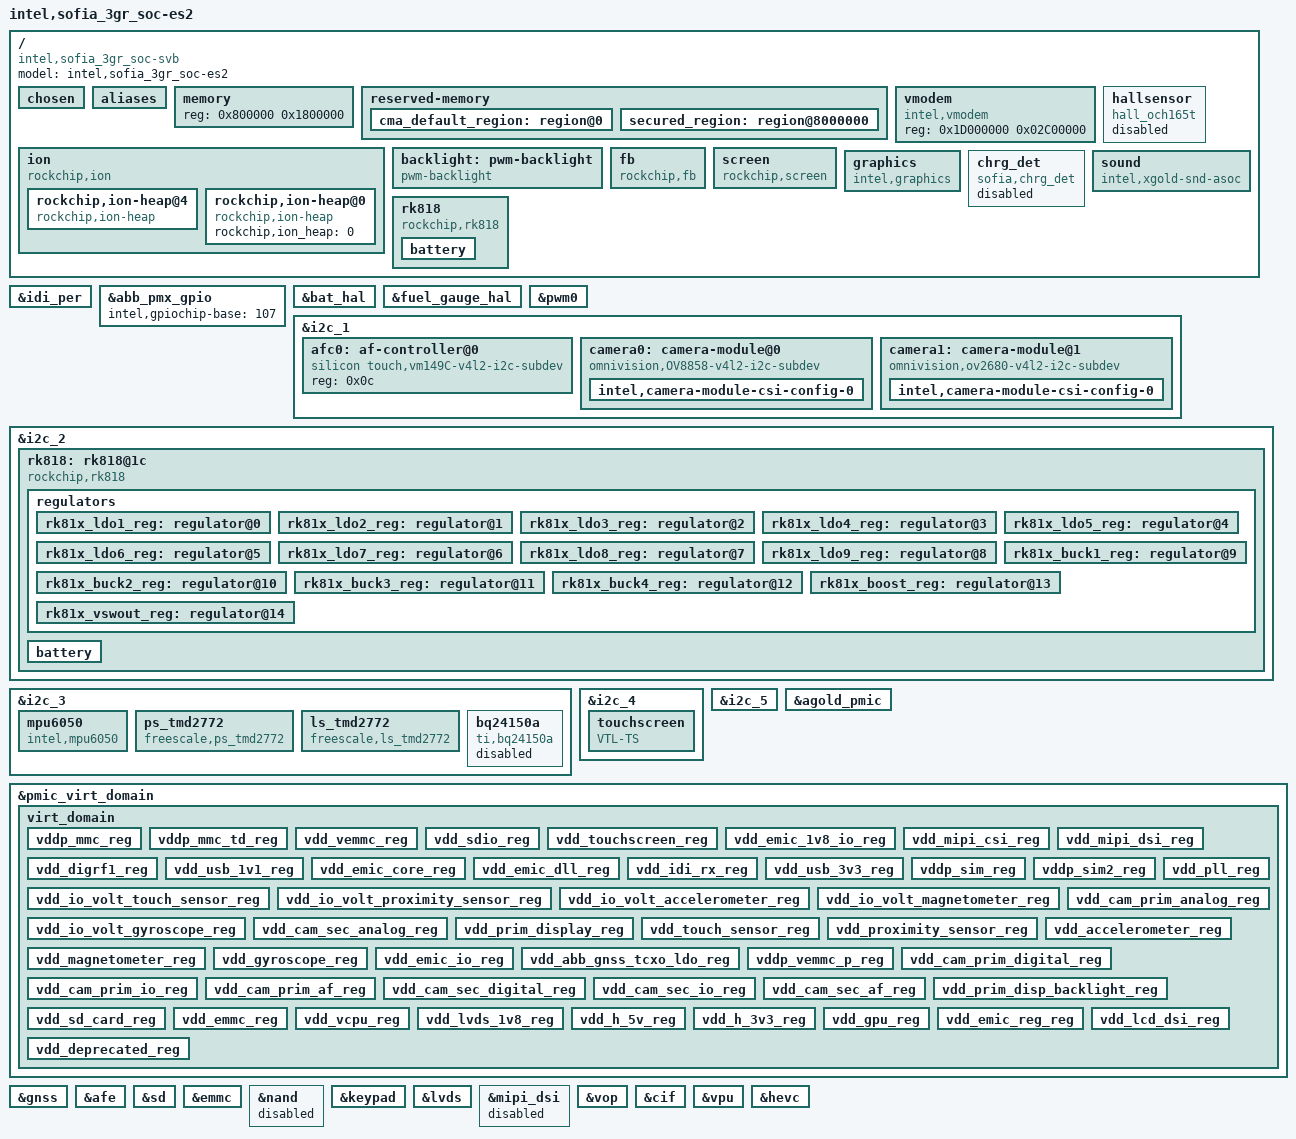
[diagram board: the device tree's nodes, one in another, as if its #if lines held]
/dts-v1/;
#include "xgold/sofia_3gr_soc/irq.h"
#include <dt-bindings/sensor-dev.h>
#include <dt-bindings/sofiafb/sofia_fb.h>
/ {
	#address-cells = <1>;
	#size-cells = <1>;
	model = "intel,sofia_3gr_soc-es2";
	compatible = "intel,sofia_3gr_soc-svb", "intel,xgold";

	#include "xgold/sofia_3gr_soc/sofia_3gr_soc.dtsi"
	#include "xgold/sofia_3gr_soc/irq.dtsi"
	#include "xgold/mobilevisor/mobilevisor.dtsi"
	#include "xgold/sofia_3gr_soc/clock-es1.dtsi"
	#include "xgold/sofia_3gr_soc/regulator.dtsi"
	#include "xgold/sofia_3gr_soc/device-pm-reg.dtsi"
	#include "xgold/sofia_3gr_soc/cpufreq.dtsi"
	#include "xgold/pmic/granite.dtsi"
	#include "xgold/pmic/agold_pmic.dtsi"
	#include "xgold/pmic/pmic_virt_domain.dtsi"
	chosen {
	};

	aliases {
	};

	memory {
		device_type = "memory";
		reg = <0x800000 0x1800000>;
	};

	reserved-memory {
		#address-cells = <1>;
		#size-cells = <1>;
		ranges;

		/* global autoconfigured region for contiguous allocations */
		cma_default_region: region@0 {
			size = <0x08000000>;
			limit = <0x10000000>;
			linux,cma-default;
		};
		/* special region for secured processing devices */
		secured_region: region@8000000 {
			reg = <0x08000000 0x08000000>;
			no-map;
			linux,cma;
		};
	};

	vmodem {
		compatible = "intel,vmodem";
		reg = < 0x1D000000 0x02C00000 >;
	};

	ion {
		compatible = "rockchip,ion";
		#address-cells = < 1 >;
		#size-cells = < 0 >;
		rockchip,ion-heap@4 {
			compatible = "rockchip,ion-heap";
			rockchip,ion_heap = < 4 >;
			reg = < 0x00000000 0x08000000 >;
		};
		rockchip,ion-heap@0 {
			compatible = "rockchip,ion-heap";
			rockchip,ion_heap = < 0 >;
		};
	};

	backlight: pwm-backlight {
                compatible = "pwm-backlight";
                reg = <0xE1A00000 0x10>;
                brightness-levels = <
                         20  20  20  20  20  20  20  20
                         20  20  20  20  20  20  20  20
                         20  20  20  20  20  21  22  23
                         24  25  26  27  28  29  30  31
                         32  33  34  35  36  37  38  39
                         40  41  42  43  44  45  46  47
                         48  49  50  51  52  53  54  55
                         56  57  58  59  60  61  62  63
                         64  65  66  67  68  69  70  71
                         72  73  74  75  76  77  78  79
                         80  81  82  83  84  85  86  87
                         88  89  90  91  92  93  94  95
                         96  97  98  99 100 101 102 103
                        104 105 106 107 108 109 110 111
                        112 113 114 115 116 117 118 119
                        120 121 122 123 124 125 126 127
                        128 129 130 131 132 133 134 135
                        136 137 138 139 140 141 142 143
                        144 145 146 147 148 149 150 151
                        152 153 154 155 156 157 158 159
                        160 161 162 163 164 165 166 167
                        168 169 170 171 172 173 174 175
                        176 177 178 179 180 181 182 183
                        184 185 186 187 188 189 190 191
                        192 193 194 195 196 197 198 199
                        200 201 202 203 204 205 206 207
                        208 209 210 211 212 213 214 215
                        216 217 218 219 220 221 222 223
                        224 225 226 227 228 229 230 231
                        232 233 234 235 236 237 238 239
                        240 241 242 243 244 245 246 247
                        248 249 250 251 252 253 254 255>;
                default-brightness-level = <128>;
                enable-gpios = <&abb_pmx_gpio 32 0>;
                pinctrl-names = "default", "sleep", "inactive";
                pinctrl-0 = <&led_agold_default_pins>;
                pinctrl-1 = <&led_agold_sleep_pins>;
                pinctrl-2 = <&led_agold_inactive_pins>;
                pwms = <&pwm0 0 25000 PWM_POLARITY_INVERTED>;
                dev-name = "lcd-backlight";
        };

	hallsensor {
		compatible = "hall_och165t";
	  	interrupt-parent = <&eint>;
	  	interrupts = <EINT_EXI11 XGOLD_IRQ_TYPE_EDGE_FALLING>;
	  	pinctrl-names = "default", "sleep", "inactive";
	  	pinctrl-0 = <&hall_default_pins>;
	  	pinctrl-1 = <&hall_sleep_pins>;
	  	pinctrl-2 = <&hall_inactive_pins>;
		irq-gpio = <&xgold_pmx_gpio 32 IRQ_TYPE_LEVEL_LOW>;
		status = "disabled";
	};

#ifndef RECOVERY_KERNEL
	/*headset:headset {
		compatible = "intel,headset";
		#address-cells = < 0 >;
		reg = <0xE6501C00 0x4>;
		reg-names = "headset-registers";
		interrupts = < 0 1 >;
		interrupt-parent = < &headset>;
		#interrupt-cells = < 1 >;
		interrupt-map = <
			 0 &ag620_pmu ABB_PMU_ACD1 XGOLD_IRQ_TYPE_NONE
			 1 &ag620_pmu ABB_PMU_ACD2 XGOLD_IRQ_TYPE_NONE
			>;
		interrupt-names = "acd1", "acd2";
		io-channel-names = "ACCID_ADC";
		io-channels = < &meas 4 >;
	};*/
#endif
	fb {
		compatible = "rockchip,fb";
		rockchip,disp-mode = <NO_DUAL>;
		rockchip,loader-logo-on = <1>;
		rockchip,ion-drv = "rockchip";
	};

	screen {
		compatible = "rockchip,screen", "intel,screen";
		pm,class-name = "generic_class";
		pm,user-name = "lcd";
		pm,state-D0 = "enable";
		pm,state-D3 = "disable";
		backlight = <&backlight>;

		#include "xgold/display/lcd-claa070wp03xg.dtsi"
	};

	graphics {
		compatible = "intel,graphics";
		intel,gpu-shared-mem = <0x20000000>;
		intel,dcc-fbpixelformat= "RGB888";
		intel,dcc-debug-level = <1>;
		intel,fb-api = <1>;
#ifdef RECOVERY_KERNEL
		intel,dcc-mem = < 0x00800000 >;
#else
		intel,dcc-use-fences = <1>;
		intel,dcc-mem = < 0x00400000 >;
		intel,prot-mem = < 0x08000000 0x08000000>;
#endif
	};

	chrg_det: chrg_det {
		compatible = "sofia,chrg_det";
		status = "disabled";
	};

#ifndef RECOVERY_KERNEL
	sound {
		compatible = "intel,xgold-snd-asoc";
		intel,audio-codec = < &afe >;
		intel,pcm-audio = <&pcm_music>;
		intel,pcm-voice = <&pcm_voice>;
		intel,speech = <&speech_probe>;
		intel,jack = <&headset>;
	};
#endif
	rk818 {
		compatible = "rockchip,rk818";
		status = "okay";
		interrupt-parent = <&eint>;
		interrupts = < EINT_EXI3 XGOLD_IRQ_TYPE_EDGE_FALLING >;
		pinctrl-names = "default", "sleep", "inactive";
		pinctrl-0 = <&pmu_default_pins>;
		pinctrl-1 = <&pmu_sleep_pins>;
		pinctrl-2 = <&pmu_inactive_pins>;
		battery {
			ocv_table = <3350 3677 3693 3719 3752 3770 3775 3778 3785 3796 3812 3839 3881 3907 3933 3958 3978 4033 4087 4123 4174>;
			design_capacity = <4000>;
			design_qmax = <4100>;
			max_overcharge = <100>;
			max_charge_currentmA = <1500>;
			max_charge_voltagemV = <4260>;
			max_bat_voltagemV = <4200>;
			sleep_enter_current = <150>;
			sleep_exit_current = <180>;
		};
	};
};


&idi_per {
	#include "xgold/agold620/agold620.dtsi"
};

&abb_pmx_gpio {
       intel,gpiochip-base = <107>;
};

&bat_hal {
	#define BAT_TYPE_LC 0
	#define POWER_SUPPLY_TECHNOLOGY_LION 2

	supp_batids =  < 0 BAT_TYPE_LC >;

	supp_batids-map = "standrd";

	prof-standrd = < POWER_SUPPLY_TECHNOLOGY_LION /*battery_type*/
				  1630 /*capacity*/
				  4250 /*voltage_max*/
				  82 /*chrg_term_ma*/
				  3200 /*low_batt_mv*/
				  60 /*disch_tmp_ul*/
				  0xffffffec /*disch_tmp_ll (-20)*/
				  0 /*min_temp*/
				  3 /*min_temp_restart*/
				  42 /*max_temp_restart*/ >;

	prof-standrd-cap_to_vbat_ocv = <
		3227 3386 3478 3542 3591 3628 3650 3660 3665 3668
		3671 3674 3676 3681 3687 3694 3699 3704 3709 3713
		3718 3722 3726 3729 3732 3735 3737 3740 3743 3746
		3748 3751 3753 3755 3756 3758 3760 3762 3764 3766
		3768 3770 3772 3775 3777 3779 3782 3785 3787 3790
		3793 3796 3800 3803 3806 3810 3813 3817 3821 3826
		3830 3835 3841 3847 3853 3860 3867 3874 3881 3888
		3895 3901 3908 3914 3920 3926 3933 3939 3945 3952
		3958 3964 3970 3975 3981 3987 3994 4002 4013 4025
		4036 4045 4053 4060 4067 4075 4083 4093 4102 4112
		4124 >;


	prof-standrd-ntemp_ranges = <1>;

	prof-standrd-temp_range0 = < 45 /*max_temp*/
					     4160 /*full_chrg_vol*/
					     850 /*full_chrg_cur*/
					     98 /*charging_res_cap*/
					     4160 /*maint_chrg_vol_ul*/
					     850 /*maint_chrg_cur*/ >;

	nprofiles = <1>;
};

&fuel_gauge_hal {
	sense_resistor_mohm = <20>;
	gain_error_1_uc_per_mc = <30>;
	gain_error_2_uc_per_mc = <30>;
};

/*&usif1 {
	pinctrl-names = "default", "sleep", "inactive";
	pinctrl-0 = <&usif2_default_pins>;
	pinctrl-1 = <&usif2_sleep_pins>;
	pinctrl-2 = <&usif2_inactive_pins>;
};
*/
/*
&usif2 {
	pinctrl-names = "default", "sleep", "inactive";
	pinctrl-0 = <&usif2_function_B_active_pins>;
	pinctrl-1 = <&usif2_function_B_sleep_pins>;
	pinctrl-2 = <&usif2_function_B_inactive_pins>;
};
*/

&pwm0 {
	pinctrl-names = "default", "sleep", "inactive";
	pinctrl-0 = <&pwm0_default_pins>;
	pinctrl-1 = <&pwm0_sleep_pins>;
	pinctrl-2 = <&pwm0_inactive_pins>;
	status = "okay";
};

&i2c_1 {
	status = "okay";
	pinctrl-names = "default", "sleep", "inactive";
	pinctrl-0 = <&i2c1_default_pins>;
	pinctrl-1 = <&i2c1_sleep_pins>;
	pinctrl-2 = <&i2c1_inactive_pins>;

#ifndef RECOVERY_KERNEL
	#if CONFIG_VIDEO_OV8858
	afc0: af-controller@0 {
		compatible = "silicon touch,vm149C-v4l2-i2c-subdev";
		reg = < 0x0c >;
	};

	camera0: camera-module@0 {
		compatible = "omnivision,OV8858-v4l2-i2c-subdev";
		reg = < 0x10 >;/*addr is 0x6C when SID set 0,else is 0x20*/
		device_type = "v4l2-i2c-subdev";

		pinctrl-names = "default", "sleep", "inactive";
		pinctrl-0 = <&cam1_default_pins>;
		pinctrl-1 = <&cam1_sleep_pins>;
		pinctrl-2 = <&cam1_inactive_pins>;

		intel,pd-gpio = <&xgold_pmx_gpio 100 0>;
		//intel,pd-gpio_1v2 = <&xgold_pmx_gpio 68 0>;
		intel,pd-gpio-is_active_low;
		//intel,flash-gpio = <&xgold_pmx_gpio 97 0>;
		//intel,torch-gpio = <&xgold_pmx_gpio 96 0>;

		pm,class-name = "generic_class";
		pm,user-name = "primcam";
		pm,state-D0 = "enable";
		pm,state-D3 = "disable";

		intel,camera-module-facing = "back";
		intel,camera-module-mounting = "landscape";
		intel,camera-module-flash-support = <1>;
		intel,camera-module-flash-exp-time = <5000>;

		intel,af-ctrl = <&afc0>;
		intel,camera-module-csi-config-0 {
			intel,csi-pixels-per-second = <0>;
			intel,csi-vc = <0>;
			intel,csi-lanes = <4>;
			intel,csi-dphy1 = <0x600E183>;
			intel,csi-dphy2 = <0x00>;
			intel,csi-ana-bandgap-bias = <3>;
		};
	};
	#endif
#endif

#ifndef RECOVERY_KERNEL
#if CONFIG_VIDEO_OV2680
	camera1: camera-module@1 {
		compatible = "omnivision,ov2680-v4l2-i2c-subdev";
		reg = < 0x36 >;/*addr is 0x6C when SID set 0,else is 0x20*/
		device_type = "v4l2-i2c-subdev";

		pinctrl-names = "default", "sleep", "inactive";
		pinctrl-0 = <&cam2_default_pins>;
		pinctrl-1 = <&cam2_sleep_pins>;
		pinctrl-2 = <&cam2_inactive_pins>;

		intel,pd-gpio = <&xgold_pmx_gpio 99>;
		intel,pd-gpio-is_active_low;

		pm,class-name = "generic_class";
		pm,user-name = "seccam";
		pm,state-D0 = "enable";
		pm,state-D3 = "disable";

		intel,camera-module-facing = "front";
		intel,camera-module-mounting = "landscape";
		intel,camera-module-flash-support = <1>;
		intel,camera-module-flash-exp-time = <5000>;

		intel,camera-module-csi-config-0 {
			intel,csi-pixels-per-second = <0>;
			intel,csi-vc = <0>;
			intel,csi-lanes = <1>;
			intel,csi-dphy1 = <0x6284183>;
			intel,csi-dphy2 = <0x00>;
			intel,csi-ana-bandgap-bias = <3>;
		};

	};
#endif
#endif

};

&i2c_2 {
	status = "okay";

	rk818: rk818@1c {
		reg = <0x1c>;
		status = "okay";
		compatible = "rockchip,rk818";
		interrupt-parent = <&eint>;
		interrupts = < EINT_EXI3 XGOLD_IRQ_TYPE_EDGE_FALLING >;
		pinctrl-names = "default", "sleep", "inactive";
		pinctrl-0 = <&pmu_default_pins>;
		pinctrl-1 = <&pmu_sleep_pins>;
		pinctrl-2 = <&pmu_inactive_pins>;
		notify_usb_det = <0>;
		regulators {
			rk81x_ldo1_reg: regulator@0 {
				regulator-name = "rk_ldo1";
				regulator-domain = <PMIC_DOMAIN_PMIC_LDO1>;
				regulator-init-pulldown = <PMIC_PULLDOWN_FIXED>;
				regulator-init-mode = <PMIC_MODE_OFF>;
				regulator-init-voltage = <PMIC_VOLTAGE_1V80>;
				regulator-81x-init-mode = <PMIC_MODE_ON>;
				regulator-81x-init-volt = <PMIC_VOLTAGE_1V80>;
			};
			rk81x_ldo2_reg: regulator@1 {
				regulator-name = "rk_ldo2";
				regulator-domain = <PMIC_DOMAIN_PMIC_LDO2>;
				regulator-init-pulldown = <PMIC_PULLDOWN_FIXED>;
				regulator-init-mode = <PMIC_MODE_OFF>;
				regulator-init-voltage = <PMIC_VOLTAGE_1V80>;
				regulator-81x-init-mode = <PMIC_MODE_ON>;
				regulator-81x-init-volt = <PMIC_VOLTAGE_2V50>;
			};
			rk81x_ldo3_reg: regulator@2 {
				regulator-name = "rk_ldo3";
				regulator-domain = <PMIC_DOMAIN_PMIC_LDO3>;
				regulator-init-pulldown = <PMIC_PULLDOWN_FIXED>;
				regulator-init-mode = <PMIC_MODE_OFF>;
				regulator-init-voltage = <PMIC_VOLTAGE_1V80>;
				regulator-81x-init-mode = <PMIC_MODE_ON>;
				regulator-81x-init-volt = <PMIC_VOLTAGE_1V80>;
			};
			rk81x_ldo4_reg: regulator@3 {
				regulator-name = "rk_ldo4";
				regulator-domain = <PMIC_DOMAIN_PMIC_LDO4>;
				regulator-init-pulldown = <PMIC_PULLDOWN_FIXED>;
				regulator-init-mode = <PMIC_MODE_ON>;
				regulator-init-voltage = <PMIC_VOLTAGE_1V80>;
				regulator-81x-init-mode = <PMIC_MODE_ON>;
				regulator-81x-init-volt = <PMIC_VOLTAGE_1V80>;
			};
			rk81x_ldo5_reg: regulator@4 {
				regulator-name = "rk_ldo5";
				regulator-domain = <PMIC_DOMAIN_PMIC_LDO5>;
				regulator-init-pulldown = <PMIC_PULLDOWN_FIXED>;
				regulator-init-mode = <PMIC_MODE_ON>;
				regulator-init-voltage = <PMIC_VOLTAGE_1V80>;
				regulator-81x-init-mode = <PMIC_MODE_ON>;
				regulator-81x-init-volt = <PMIC_VOLTAGE_1V80>;
			};
			rk81x_ldo6_reg: regulator@5 {
				regulator-name = "rk_ldo6";
				regulator-domain = <PMIC_DOMAIN_PMIC_LDO6>;
				regulator-init-pulldown = <PMIC_PULLDOWN_FIXED>;
				regulator-init-mode = <PMIC_MODE_OFF>;
				regulator-init-voltage = <PMIC_VOLTAGE_FIXED>;
				regulator-81x-init-mode = <PMIC_MODE_ON>;
				regulator-81x-init-volt = <PMIC_VOLTAGE_1V20>;
			};
			rk81x_ldo7_reg: regulator@6 {
				regulator-name = "rk_ldo7";
				regulator-domain = <PMIC_DOMAIN_PMIC_LDO7>;
				regulator-init-pulldown = <PMIC_PULLDOWN_FIXED>;
				regulator-init-mode = <PMIC_MODE_OFF>;
				regulator-init-voltage = <PMIC_VOLTAGE_FIXED>;
				regulator-81x-init-mode = <PMIC_MODE_ON>;
				regulator-81x-init-volt = <PMIC_VOLTAGE_1V20>;
			};
			rk81x_ldo8_reg: regulator@7 {
				regulator-name = "rk_ldo8";
				regulator-domain = <PMIC_DOMAIN_PMIC_LDO8>;
				regulator-init-pulldown = <PMIC_PULLDOWN_FIXED>;
				regulator-init-mode = <PMIC_MODE_ON>;
				regulator-init-voltage = <PMIC_VOLTAGE_3V00>;
				regulator-81x-init-mode = <PMIC_MODE_ON>;
				regulator-81x-init-volt = <PMIC_VOLTAGE_3V00>;
			};
			rk81x_ldo9_reg: regulator@8 {
				regulator-name = "rk_ldo9";
				regulator-domain = <PMIC_DOMAIN_PMIC_LDO9>;
				regulator-init-pulldown = <PMIC_PULLDOWN_FIXED>;
				regulator-init-mode = <PMIC_MODE_OFF>;
				regulator-init-voltage = <PMIC_VOLTAGE_FIXED>;
				regulator-81x-init-mode = <PMIC_MODE_ON>;
				regulator-81x-init-volt = <PMIC_VOLTAGE_1V80>;
			};
			rk81x_buck1_reg: regulator@9 {
				regulator-name = "rk_buck1";
				regulator-domain = <PMIC_DOMAIN_PMIC_BUCK1>;
				regulator-init-pulldown = <PMIC_PULLDOWN_FIXED>;
				regulator-init-mode = <PMIC_MODE_ON>;
				regulator-init-voltage = <PMIC_VOLTAGE_1V10>;
				regulator-81x-init-mode = <PMIC_MODE_ON>;
				regulator-81x-init-volt = <PMIC_VOLTAGE_1V30>;
			};
			rk81x_buck2_reg: regulator@10 {
				regulator-name = "rk_buck2";
				regulator-domain = <PMIC_DOMAIN_PMIC_BUCK2>;
				regulator-init-pulldown = <PMIC_PULLDOWN_FIXED>;
				regulator-init-mode = <PMIC_MODE_ON>;
				regulator-init-voltage = <PMIC_VOLTAGE_1V10>;
				regulator-81x-init-mode = <PMIC_MODE_ON>;
				regulator-81x-init-volt = <PMIC_VOLTAGE_1V20>;
			};
			rk81x_buck3_reg: regulator@11 {
				regulator-name = "rk_buck3";
				regulator-domain = <PMIC_DOMAIN_PMIC_BUCK3>;
				regulator-init-pulldown = <PMIC_PULLDOWN_FIXED>;
				regulator-init-mode = <PMIC_MODE_OFF>;
				regulator-init-voltage = <PMIC_VOLTAGE_1V20>;
				regulator-81x-init-mode = <PMIC_MODE_ON>;
				regulator-81x-init-volt = <PMIC_VOLTAGE_1V20>;
			};
			rk81x_buck4_reg: regulator@12 {
				regulator-name = "rk_buck4";
				regulator-domain = <PMIC_DOMAIN_PMIC_BUCK4>;
				regulator-init-pulldown = <PMIC_PULLDOWN_FIXED>;
				regulator-init-mode = <PMIC_MODE_OFF>;
				regulator-init-voltage = <PMIC_VOLTAGE_3V30>;
				regulator-81x-init-mode = <PMIC_MODE_ON>;
				regulator-81x-init-volt = <PMIC_VOLTAGE_3V30>;
			};
			rk81x_boost_reg: regulator@13 {
				regulator-name = "rk_boost";
				regulator-domain = <PMIC_DOMAIN_PMIC_BOOST>;
				regulator-init-pulldown = <PMIC_PULLDOWN_FIXED>;
				regulator-init-mode = <PMIC_MODE_OFF>;
				regulator-init-voltage = <PMIC_VOLTAGE_5V00>;
				regulator-81x-init-mode = <PMIC_MODE_ON>;
				regulator-81x-init-volt = <PMIC_VOLTAGE_5V00>;
			};
			rk81x_vswout_reg: regulator@14 {
				regulator-name = "rk_vswout";
				regulator-domain = <PMIC_DOMAIN_PMIC_VSWOUT>;
				regulator-init-pulldown = <PMIC_PULLDOWN_FIXED>;
				regulator-init-mode = <PMIC_MODE_OFF>;
				regulator-init-voltage = <PMIC_VOLTAGE_3V00>;
				regulator-81x-init-mode = <PMIC_MODE_ON>;
				regulator-81x-init-volt = <PMIC_VOLTAGE_3V00>;
			};
		};
		battery {
			ocv_table = <3350 3677 3693 3719 3752 3770 3775
				     3778 3785 3796 3812 3839 3881 3907
				     3933 3958 3978 4033 4087 4123 4174>;
			design_capacity = <4000>;
			design_qmax = <4100>;
			max_overcharge = <100>;
			max_charge_currentmA = <1500>;
			max_charge_voltagemV = <4260>;
			max_bat_voltagemV = <4200>;
			sleep_enter_current = <150>;
			sleep_exit_current = <180>;
			virtual_power = <1>;
		};
	};
};

&i2c_3 {
	status = "okay";
	pinctrl-names = "default", "sleep", "inactive";
	pinctrl-0 = <&i2c3_default_pins>;
	pinctrl-1 = <&i2c3_sleep_pins>;
	pinctrl-2 = <&i2c3_inactive_pins>;

	mpu6050 {
        	compatible = "intel,mpu6050";
        	reg = <0x68>;
                interrupt-parent = <&eint>;
                interrupts = < EINT_EXI7 XGOLD_IRQ_TYPE_EDGE_RISING >;
                pinctrl-names = "default", "sleep", "inactive";
                pinctrl-0 = <&gyroscope_default_pins>;
                pinctrl-1 = <&gyroscope_sleep_pins>;
                pinctrl-2 = <&gyroscope_inactive_pins>;
       		mpu-int_config = <0x10>;
       	        mpu-level_shifter = <0>;
        	mpu-orientation = <0 1 0 1 0 0 0 0 1>;
        	orientation-x= <1>;
        	orientation-y= <0>;
        	orientation-z= <0>;
        	irq-gpio = <&xgold_pmx_gpio 5>;
        	mpu-debug = <1>;
		pm,class-name = "mpu6050_class";
		pm,user-name = "gyroscope";
		pm,state-D0 = "enable";
		pm,state-D3 = "disable";
        };
	ps_tmd2772 {
          	compatible = "freescale,ps_tmd2772";
          	reg = <0x38>;
          	type = <SENSOR_TYPE_PROXIMITY>;
	  	interrupt-parent = <&eint>;
	  	interrupts = < EINT_EXI5 XGOLD_IRQ_TYPE_LEVEL_LOW >;
	  	pinctrl-names = "default", "sleep", "inactive";
	  	pinctrl-0 = <&prox_default_pins>;
	  	pinctrl-1 = <&prox_sleep_pins>;
	  	pinctrl-2 = <&prox_inactive_pins>;
		irq-gpio = <&xgold_pmx_gpio 0 IRQ_TYPE_LEVEL_LOW>;
          	irq_enable = <0>;
          	poll_delay_ms = <200>;
          	layout = <1>;
	  	pm,class-name = "ps_tmd2772_class";
	  	pm,user-name = "gyroscope";
   	};
   	ls_tmd2772 {
          	compatible = "freescale,ls_tmd2772";
          	reg = <0x39>;
          	type = <SENSOR_TYPE_LIGHT>;
          	irq_enable = <0>;
          	poll_delay_ms = <200>;
          	layout = <1>;
	  	pm,class-name = "ls_tmd2772_class";
	  	pm,user-name = "gyroscope";
   	};

	bq24150a {
                status = "disabled";
                compatible = "ti,bq24150a";
                reg = <0x6a>;
                ti,current-limit = <100>;
                ti,weak-battery-voltage = <3400>;
                ti,battery-regulation-voltage = <4200>;
                ti,charge-current = <650>;
                ti,termination-current = <100>;
                ti,resistor-sense = <68>;

                ti,usb-charger-detection = <&chrg_det>;
        };

};

&i2c_4 {
	status = "okay";
	pinctrl-names = "default", "sleep", "inactive";
	pinctrl-0 = <&i2c4_default_pins>;
	pinctrl-1 = <&i2c4_sleep_pins>;
	pinctrl-2 = <&i2c4_inactive_pins>;
	touchscreen {
		compatible = "VTL-TS";
		reg = < 0x01 >;
		interrupt-parent = <&eint>;
		xy-swap-enable = < 1 >;
		x-reverse-enable = < 0 >;
		y-reverse-enable = < 1 >;
		chip-diff = < 1 >; /* 1:CT362,2:CT363S(1080P) */
		interrupts = < EINT_EXI12 XGOLD_IRQ_TYPE_EDGE_FALLING >;
		pinctrl-names = "default", "sleep", "inactive";
		pinctrl-0 = <&touch_default_pins>;
		pinctrl-1 = <&touch_sleep_pins>;
		pinctrl-2 = <&touch_inactive_pins>;
		intel,ts-gpio-reset = <&xgold_pmx_gpio 19 0>;
		intel,ts-gpio-irq = <&xgold_pmx_gpio 18 0>;
		pm,class-name = "gt9xx_class";
		pm,user-name = "tp";
		pm,state-D0 = "enable";
		pm,state-D3 = "disable";
		intel,max-x = <800>;
		intel,max-y = <1280>;
	};
};

&i2c_5 {
	pinctrl-names = "default", "sleep", "inactive";
	pinctrl-0 = <&i2c5_agold_default_pins>;
	pinctrl-1 = <&i2c5_agold_sleep_pins>;
	pinctrl-2 = <&i2c5_agold_inactive_pins>;

};
&agold_pmic {
	status = "okay";
};

&pmic_virt_domain {
	status = "okay";
	virt_domain {
		vddp_mmc_reg {
			virt-domain = <PMIC_VDDP_MMC>;
			pmu-domain = <PMIC_DOMAIN_LMMC1>;
		};
		vddp_mmc_td_reg {
			virt-domain = <PMIC_VDDP_MMC_TD>;
			pmu-domain = <PMIC_DOMAIN_NOTCFG>;
		};
		vdd_vemmc_reg {
			virt-domain = <PMIC_VDD_VEMMC>;
			pmu-domain = <PMIC_DOMAIN_PMIC_LDO5>;
		};
		vdd_sdio_reg {
			virt-domain = <PMIC_VDD_SDIO>;
			pmu-domain = <PMIC_DOMAIN_NOTCFG>;
		};
		vdd_touchscreen_reg {
			virt-domain = <PMIC_VDD_TOUCHSCREEN>;
			pmu-domain = <PMIC_DOMAIN_PMIC_VSWOUT>;
		};
		vdd_emic_1v8_io_reg {
			virt-domain = <PMIC_VDD_EMIC_1V8_IO>;
			pmu-domain = <PMIC_DOMAIN_PMIC_BUCK3>;
		};
		vdd_mipi_csi_reg {
			virt-domain = <PMIC_VDD_MIPI_CSI>;
			pmu-domain = <PMIC_DOMAIN_LMIPI>;
		};
		vdd_mipi_dsi_reg {
			virt-domain = <PMIC_VDD_MIPI_DSI>;
			pmu-domain = <PMIC_DOMAIN_LMIPI>;
		};
		vdd_digrf1_reg {
			virt-domain = <PMIC_VDD_DIGRF1>;
			pmu-domain = <PMIC_DOMAIN_LMIPI>;
		};
		vdd_usb_1v1_reg {
			virt-domain = <PMIC_VDD_USB_1V1>;
			pmu-domain = <PMIC_DOMAIN_LAIF>;
		};
		vdd_emic_core_reg {
			virt-domain = <PMIC_VDD_EMIC_CORE>;
			pmu-domain = <PMIC_DOMAIN_PMIC_LDO7>;
		};
		vdd_emic_dll_reg {
			virt-domain = <PMIC_VDD_EMIC_DLL>;
			pmu-domain = <PMIC_DOMAIN_PMIC_LDO3>;
		};
		vdd_idi_rx_reg {
			virt-domain = <PMIC_VDD_IDI_RX>;
			pmu-domain = <PMIC_DOMAIN_LAIF>;
		};
		vdd_usb_3v3_reg {
			virt-domain = <PMIC_VDD_USB_3V3>;
			pmu-domain = <PMIC_DOMAIN_LUSB>;
		};
		vddp_sim_reg {
			virt-domain = <PMIC_VDDP_SIM>;
			pmu-domain = <PMIC_DOMAIN_LSIM1>;
		};
		vddp_sim2_reg {
			virt-domain = <PMIC_VDDP_SIM2>;
			pmu-domain = <PMIC_DOMAIN_LSIM2>;
		};
		vdd_pll_reg {
			virt-domain = <PMIC_VDD_PLL>;
			pmu-domain = <PMIC_DOMAIN_LPLL>;
		};
		vdd_io_volt_touch_sensor_reg {
			virt-domain = <PMIC_VDD_IO_VOLT_TOUCH_SENSOR>;
			pmu-domain = <PMIC_DOMAIN_NOTCFG>;
		};
		vdd_io_volt_proximity_sensor_reg {
			virt-domain = <PMIC_VDD_IO_VOLT_PROXIMITY_SENSOR>;
			pmu-domain = <PMIC_DOMAIN_PMIC_LDO5>;
		};
		vdd_io_volt_accelerometer_reg {
			virt-domain = <PMIC_VDD_IO_VOLT_ACCELEROMETER>;
			pmu-domain = <PMIC_DOMAIN_PMIC_LDO5>;
		};
		vdd_io_volt_magnetometer_reg {
			virt-domain = <PMIC_VDD_IO_VOLT_MAGNETOMETER>;
			pmu-domain = <PMIC_DOMAIN_PMIC_LDO5>;
		};
		vdd_io_volt_gyroscope_reg {
			virt-domain = <PMIC_VDD_IO_VOLT_GYROSCOPE>;
			pmu-domain = <PMIC_DOMAIN_PMIC_LDO5>;
		};
		vdd_cam_prim_analog_reg {
			virt-domain = <PMIC_VDD_CAM_PRIM_ANALOG>;
			pmu-domain = <PMIC_DOMAIN_LAUX1>;
		};
		vdd_cam_sec_analog_reg {
			virt-domain = <PMIC_VDD_CAM_SEC_ANALOG>;
			pmu-domain = <PMIC_DOMAIN_LAUX1>;
		};
		vdd_prim_display_reg {
			virt-domain = <PMIC_VDD_PRIM_DISPLAY>;
			pmu-domain = <PMIC_DOMAIN_PMIC_VSWOUT>;
		};
		vdd_touch_sensor_reg {
			virt-domain = <PMIC_VDD_TOUCH_SENSOR>;
			pmu-domain = <PMIC_DOMAIN_NOTCFG>;
		};
		vdd_proximity_sensor_reg {
			virt-domain = <PMIC_VDD_PROXIMITY_SENSOR>;
			pmu-domain = <PMIC_DOMAIN_LAUX2>;
		};
		vdd_accelerometer_reg {
			virt-domain = <PMIC_VDD_ACCELEROMETER>;
			pmu-domain = <PMIC_DOMAIN_LAUX2>;
		};
		vdd_magnetometer_reg {
			virt-domain = <PMIC_VDD_MAGNETOMETER>;
			pmu-domain = <PMIC_DOMAIN_LAUX2>;
		};
		vdd_gyroscope_reg {
			virt-domain = <PMIC_VDD_GYROSCOPE>;
			pmu-domain = <PMIC_DOMAIN_LAUX2>;
		};
		vdd_emic_io_reg {
			virt-domain = <PMIC_VDD_EMIC_IO>;
			pmu-domain = <PMIC_DOMAIN_LMEM>;
		};
		vdd_abb_gnss_tcxo_ldo_reg {
			virt-domain = <PMIC_VDD_ABB_GNSS_TCXO_LDO>;
			pmu-domain = <PMIC_DOMAIN_GNSS_TCXO_LDO>;
		};
		vddp_vemmc_p_reg {
			virt-domain = <PMIC_VDDP_VEMMC_P>;
			pmu-domain = <PMIC_DOMAIN_NOTCFG>;
		};
		vdd_cam_prim_digital_reg {
			virt-domain = <PMIC_VDD_CAM_PRIM_DIGITAL>;
			pmu-domain = <PMIC_DOMAIN_NOTCFG>;
		};
		vdd_cam_prim_io_reg {
			virt-domain = <PMIC_VDD_CAM_PRIM_IO>;
			pmu-domain = <PMIC_DOMAIN_LAUX2>;
		};
		vdd_cam_prim_af_reg {
			virt-domain = <PMIC_VDD_CAM_PRIM_AF>;
			pmu-domain = <PMIC_DOMAIN_NOTCFG>;
		};
		vdd_cam_sec_digital_reg {
			virt-domain = <PMIC_VDD_CAM_SEC_DIGITAL>;
			pmu-domain = <PMIC_DOMAIN_NOTCFG>;
		};
		vdd_cam_sec_io_reg {
			virt-domain = <PMIC_VDD_CAM_SEC_IO>;
			pmu-domain = <PMIC_DOMAIN_LAUX2>;
		};
		vdd_cam_sec_af_reg {
			virt-domain = <PMIC_VDD_CAM_SEC_AF>;
			pmu-domain = <PMIC_DOMAIN_NOTCFG>;
		};
		vdd_prim_disp_backlight_reg {
			virt-domain = <PMIC_VDD_PRIM_DISP_BACKLIGHT>;
			pmu-domain = <PMIC_DOMAIN_NOTCFG>;
		};
		vdd_sd_card_reg {
			virt-domain = <PMIC_VDD_SD_CARD>;
			pmu-domain = <PMIC_DOMAIN_PMIC_LDO8>;
		};
		vdd_emmc_reg {
			virt-domain = <PMIC_VDD_EMMC>;
			pmu-domain = <PMIC_DOMAIN_PMIC_BUCK4>;
		};
		vdd_vcpu_reg {
			virt-domain = <PMIC_VDD_VCPU>;
			pmu-domain = <PMIC_DOMAIN_PMIC_BUCK1>;
		};
		vdd_lvds_1v8_reg {
			virt-domain = <PMIC_VDD_LVDS_1V8>;
			pmu-domain = <PMIC_DOMAIN_PMIC_LDO2>;
		};
		vdd_h_5v_reg {
			virt-domain = <PMIC_VDD_H_5V>;
			pmu-domain = <PMIC_DOMAIN_PMIC_BOOST>;
		};
		vdd_h_3v3_reg {
			virt-domain = <PMIC_VDD_H_3V3>;
			pmu-domain = <PMIC_DOMAIN_PMIC_VSWOUT>;
		};
		vdd_gpu_reg {
			virt-domain = <PMIC_VDD_GPU>;
			pmu-domain = <PMIC_DOMAIN_PMIC_BUCK2>;
		};
		vdd_emic_reg_reg {
			virt-domain = <PMIC_VDD_EMIC_RET>;
			pmu-domain = <PMIC_DOMAIN_PMIC_BUCK3>;
		};
		vdd_lcd_dsi_reg {
			virt-domain = <PMIC_VDD_LCD_DSI>;
			pmu-domain = <PMIC_DOMAIN_PMIC_LDO5>;
		};
		vdd_deprecated_reg {
			virt-domain = <PMIC_VDD_DEPRECATED>;
			pmu-domain = <PMIC_DOMAIN_NOTCFG>;
		};
	};
};

&gnss {
    pinctrl-names = "default", "sleep", "inactive", "default_lna", "inactive_lna", "default_fta", "inactive_fta", "gnss_default", "gnss_inactive";
    pinctrl-0 = <&tcxo_agold_default_pins>;
    pinctrl-1 = <&tcxo_agold_sleep_pins>;
    pinctrl-2 = <&tcxo_agold_inactive_pins>;
    pinctrl-3 = <&ext_agold_default_pins>;
    pinctrl-4 = <&ext_agold_sleep_pins>;
    pinctrl-5 = <&gnss_agold_default_pins>;
    pinctrl-6 = <&gnss_agold_sleep_pins>;
    pinctrl-7 = <&gnss_default_pins>;
    pinctrl-8 = <&gnss_inactive_pins>;
};

#ifndef RECOVERY_KERNEL
&afe {
	pinctrl-names = "default", "sleep", "inactive";
	pinctrl-0 = <&dm_agold_default_pins>;
	pinctrl-1 = <&dm_agold_sleep_pins>;
	pinctrl-2 = <&dm_agold_inactive_pins>;
};
#endif

&sd {
	intel,tap_values = <0x080400F5 0x08040004 0x00040004 0x08040004 0x5CF501A5 0x00F500A5 0x00F500A5>;
	pinctrl-names = "default", "sleep", "inactive";
	pinctrl-0 = <&sdmmc_default_pins>;
	pinctrl-1 = <&sdmmc_sleep_pins>;
	pinctrl-2 = <&sdmmc_inactive_pins>;
};

&emmc {
	intel,tap_values = <0x080400F5 0x08040004 0x00040004 0x08040004 0x08040004 0x000400B5 0x000400B5>;
	pinctrl-names = "default", "sleep", "inactive";
	pinctrl-0 = <&emmc_default_pins>;
	pinctrl-1 = <&emmc_sleep_pins>;
	pinctrl-2 = <&emmc_inactive_pins>;
	status = "okay";
};

&nand {
	pinctrl-names = "default", "sleep", "inactive";
	pinctrl-0 = <&nand_function_B_active_pins>;
	pinctrl-1 = <&nand_function_B_sleep_pins>;
	pinctrl-2 = <&nand_function_B_inactive_pins>;
        status = "disabled";
};

&keypad {
	pinctrl-names = "default", "sleep", "inactive";
	pinctrl-0 = <&kp_default_pins>;
	pinctrl-1 = <&kp_sleep_pins>;
	pinctrl-2 = <&kp_inactive_pins>;
	keypad,num-rows = <9>;
	keypad,num-columns = <8>;
	keypad,rows = <3 8>;
	keypad,columns = <3 4>;
	linux,keymap = <0x03030072	/* KEY_VOLUMEDOWN */
			0x03040073	/* KEY_VOLUMEUP */
			0x08030074	/* KEY_POWER */
			0x0804008b>;	/* KEY_MENU */
};

&lvds {
	status = "okay";

	pinctrl-names = "default", "sleep", "inactive";
	pinctrl-0 = <&lvds_default_pins>;
	pinctrl-1 = <&lvds_sleep_pins>;
	pinctrl-2 = <&lvds_inactive_pins>;
};

&mipi_dsi {
	status = "disabled";
};

&vop {
	status = "okay";
	rockchip,fb-win-map = <FB_DEFAULT_ORDER>;
	rockchip,iommu-enabled = <1>;
	pm,state-D0 = "low_perf";
};

#ifndef RECOVERY_KERNEL
&cif {
	intel,camera-modules-attached = <&camera0 &camera1>;
};

&vpu {
       status = "okay";
};

&hevc {
       status = "okay";
};
#endif
#include "xgold/agold620/pinctrl-sf_3g-es2.1-svb.dtsi"
#include "xgold/sofia_3gr_soc/pinctrl-sf_3gr-es1-svb-rk.dtsi"
